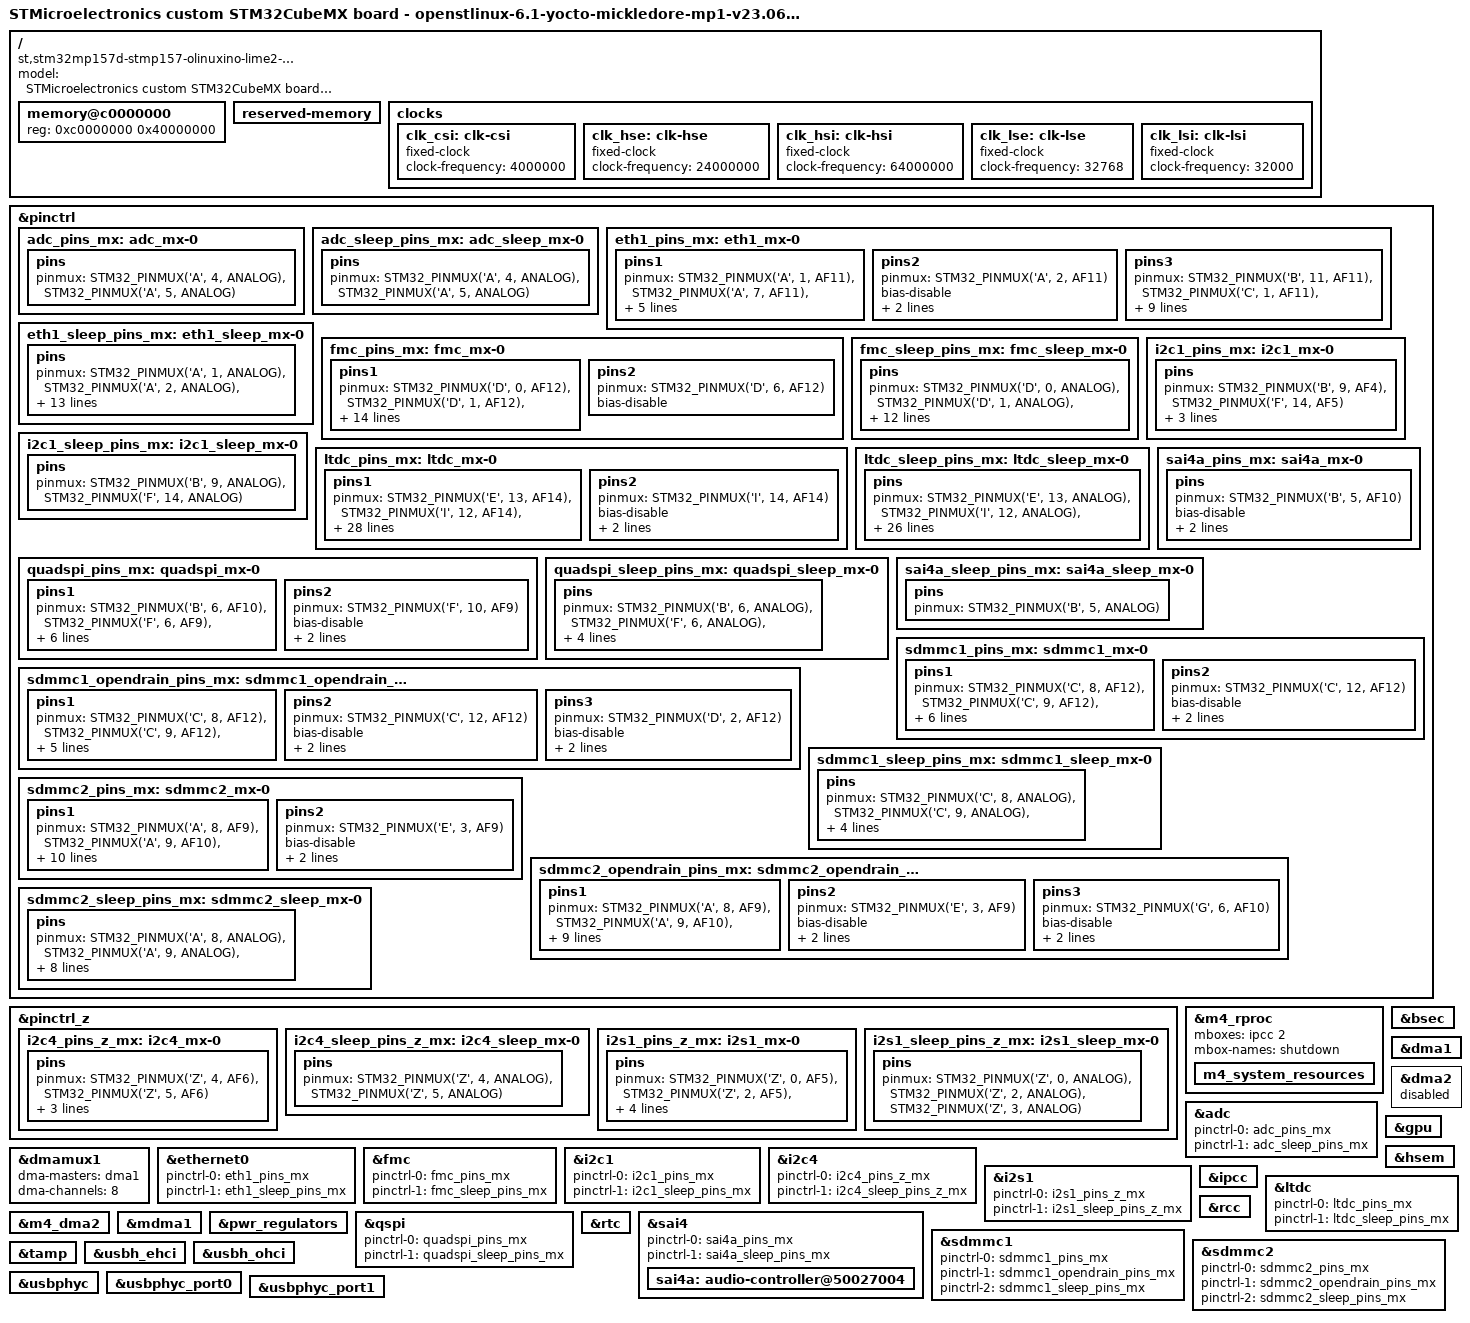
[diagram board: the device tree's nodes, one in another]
// SPDX-License-Identifier: (GPL-2.0-or-later OR BSD-3-Clause)
/*
 * Copyright (C) 2023, STMicroelectronics - All Rights Reserved
 * Author: STM32CubeMX code generation for STMicroelectronics.
 */

/* For more information on Device Tree configuration, please refer to
 * https://wiki.st.com/stm32mpu/wiki/Category:Device_tree_configuration
 */

/dts-v1/;
#include <dt-bindings/pinctrl/stm32-pinfunc.h>

#include "stm32mp157.dtsi"
#include "stm32mp15xd.dtsi"
#include "stm32mp15xxaa-pinctrl.dtsi"
#include "stm32mp15-m4-srm.dtsi"

/* USER CODE BEGIN includes */
#include "stm32mp15-scmi.dtsi"
/* USER CODE END includes */

/ {
	model = "STMicroelectronics custom STM32CubeMX board - openstlinux-6.1-yocto-mickledore-mp1-v23.06.21";
	compatible = "st,stm32mp157d-stmp157-olinuxino-lime2-mx", "st,stm32mp157";

	memory@c0000000 {
		device_type = "memory";
		reg = <0xc0000000 0x40000000>;

		/* USER CODE BEGIN memory */
		/* USER CODE END memory */
	};

	reserved-memory {
		#address-cells = <1>;
		#size-cells = <1>;
		ranges;

		/* USER CODE BEGIN reserved-memory */
		/* USER CODE END reserved-memory */
	};

	/* USER CODE BEGIN root */
	/* USER CODE END root */

	clocks{

		/* USER CODE BEGIN clocks */
		clk_csi: clk-csi {
		#clock-cells = <0>;
		compatible = "fixed-clock";
		clock-frequency = <4000000>;
		};

		clk_hse: clk-hse {
		#clock-cells = <0>;
		compatible = "fixed-clock";
		clock-frequency = <24000000>;
		};

		clk_hsi: clk-hsi {
		#clock-cells = <0>;
		compatible = "fixed-clock";
		clock-frequency = <64000000>;
		};

		clk_lse: clk-lse {
		#clock-cells = <0>;
		compatible = "fixed-clock";
		clock-frequency = <32768>;
		};

		clk_lsi: clk-lsi {
		#clock-cells = <0>;
		compatible = "fixed-clock";
		clock-frequency = <32000>;
		};				
		/* USER CODE END clocks */
	};

}; /*root*/

&pinctrl {

	adc_pins_mx: adc_mx-0 {
		pins {
			pinmux = <STM32_PINMUX('A', 4, ANALOG)>, /* ADC2_INP18 */
					 <STM32_PINMUX('A', 5, ANALOG)>; /* ADC2_INN18 */
		};
	};

	adc_sleep_pins_mx: adc_sleep_mx-0 {
		pins {
			pinmux = <STM32_PINMUX('A', 4, ANALOG)>, /* ADC2_INP18 */
					 <STM32_PINMUX('A', 5, ANALOG)>; /* ADC2_INN18 */
		};
	};

	eth1_pins_mx: eth1_mx-0 {
		pins1 {
			pinmux = <STM32_PINMUX('A', 1, AF11)>, /* ETH1_RX_CLK */
					 <STM32_PINMUX('A', 7, AF11)>, /* ETH1_RX_CTL */
					 <STM32_PINMUX('B', 0, AF11)>, /* ETH1_RXD2 */
					 <STM32_PINMUX('B', 1, AF11)>, /* ETH1_RXD3 */
					 <STM32_PINMUX('C', 4, AF11)>, /* ETH1_RXD0 */
					 <STM32_PINMUX('C', 5, AF11)>; /* ETH1_RXD1 */
			bias-disable;
		};
		pins2 {
			pinmux = <STM32_PINMUX('A', 2, AF11)>; /* ETH1_MDIO */
			bias-disable;
			drive-push-pull;
			slew-rate = <0>;
		};
		pins3 {
			pinmux = <STM32_PINMUX('B', 11, AF11)>, /* ETH1_TX_CTL */
					 <STM32_PINMUX('C', 1, AF11)>, /* ETH1_MDC */
					 <STM32_PINMUX('C', 2, AF11)>, /* ETH1_TXD2 */
					 <STM32_PINMUX('E', 2, AF11)>, /* ETH1_TXD3 */
					 <STM32_PINMUX('G', 4, AF11)>, /* ETH1_GTX_CLK */
					 <STM32_PINMUX('G', 5, AF11)>, /* ETH1_CLK125 */
					 <STM32_PINMUX('G', 13, AF11)>, /* ETH1_TXD0 */
					 <STM32_PINMUX('G', 14, AF11)>; /* ETH1_TXD1 */
			bias-disable;
			drive-push-pull;
			slew-rate = <2>;
		};
	};

	eth1_sleep_pins_mx: eth1_sleep_mx-0 {
		pins {
			pinmux = <STM32_PINMUX('A', 1, ANALOG)>, /* ETH1_RX_CLK */
					 <STM32_PINMUX('A', 2, ANALOG)>, /* ETH1_MDIO */
					 <STM32_PINMUX('A', 7, ANALOG)>, /* ETH1_RX_CTL */
					 <STM32_PINMUX('B', 0, ANALOG)>, /* ETH1_RXD2 */
					 <STM32_PINMUX('B', 1, ANALOG)>, /* ETH1_RXD3 */
					 <STM32_PINMUX('B', 11, ANALOG)>, /* ETH1_TX_CTL */
					 <STM32_PINMUX('C', 1, ANALOG)>, /* ETH1_MDC */
					 <STM32_PINMUX('C', 2, ANALOG)>, /* ETH1_TXD2 */
					 <STM32_PINMUX('C', 4, ANALOG)>, /* ETH1_RXD0 */
					 <STM32_PINMUX('C', 5, ANALOG)>, /* ETH1_RXD1 */
					 <STM32_PINMUX('E', 2, ANALOG)>, /* ETH1_TXD3 */
					 <STM32_PINMUX('G', 4, ANALOG)>, /* ETH1_GTX_CLK */
					 <STM32_PINMUX('G', 5, ANALOG)>, /* ETH1_CLK125 */
					 <STM32_PINMUX('G', 13, ANALOG)>, /* ETH1_TXD0 */
					 <STM32_PINMUX('G', 14, ANALOG)>; /* ETH1_TXD1 */
		};
	};

	fmc_pins_mx: fmc_mx-0 {
		pins1 {
			pinmux = <STM32_PINMUX('D', 0, AF12)>, /* FMC_D2 */
					 <STM32_PINMUX('D', 1, AF12)>, /* FMC_D3 */
					 <STM32_PINMUX('D', 4, AF12)>, /* FMC_NOE */
					 <STM32_PINMUX('D', 5, AF12)>, /* FMC_NWE */
					 <STM32_PINMUX('D', 11, AF12)>, /* FMC_CLE */
					 <STM32_PINMUX('D', 12, AF12)>, /* FMC_ALE */
					 <STM32_PINMUX('D', 14, AF12)>, /* FMC_D0 */
					 <STM32_PINMUX('D', 15, AF12)>, /* FMC_D1 */
					 <STM32_PINMUX('E', 7, AF12)>, /* FMC_D4 */
					 <STM32_PINMUX('E', 8, AF12)>, /* FMC_D5 */
					 <STM32_PINMUX('E', 9, AF12)>, /* FMC_D6 */
					 <STM32_PINMUX('E', 10, AF12)>, /* FMC_D7 */
					 <STM32_PINMUX('G', 9, AF12)>; /* FMC_NCE */
			bias-disable;
			drive-push-pull;
			slew-rate = <1>;
		};
		pins2 {
			pinmux = <STM32_PINMUX('D', 6, AF12)>; /* FMC_NWAIT */
			bias-disable;
		};
	};

	fmc_sleep_pins_mx: fmc_sleep_mx-0 {
		pins {
			pinmux = <STM32_PINMUX('D', 0, ANALOG)>, /* FMC_D2 */
					 <STM32_PINMUX('D', 1, ANALOG)>, /* FMC_D3 */
					 <STM32_PINMUX('D', 4, ANALOG)>, /* FMC_NOE */
					 <STM32_PINMUX('D', 5, ANALOG)>, /* FMC_NWE */
					 <STM32_PINMUX('D', 6, ANALOG)>, /* FMC_NWAIT */
					 <STM32_PINMUX('D', 11, ANALOG)>, /* FMC_CLE */
					 <STM32_PINMUX('D', 12, ANALOG)>, /* FMC_ALE */
					 <STM32_PINMUX('D', 14, ANALOG)>, /* FMC_D0 */
					 <STM32_PINMUX('D', 15, ANALOG)>, /* FMC_D1 */
					 <STM32_PINMUX('E', 7, ANALOG)>, /* FMC_D4 */
					 <STM32_PINMUX('E', 8, ANALOG)>, /* FMC_D5 */
					 <STM32_PINMUX('E', 9, ANALOG)>, /* FMC_D6 */
					 <STM32_PINMUX('E', 10, ANALOG)>, /* FMC_D7 */
					 <STM32_PINMUX('G', 9, ANALOG)>; /* FMC_NCE */
		};
	};

	i2c1_pins_mx: i2c1_mx-0 {
		pins {
			pinmux = <STM32_PINMUX('B', 9, AF4)>, /* I2C1_SDA */
					 <STM32_PINMUX('F', 14, AF5)>; /* I2C1_SCL */
			bias-disable;
			drive-open-drain;
			slew-rate = <0>;
		};
	};

	i2c1_sleep_pins_mx: i2c1_sleep_mx-0 {
		pins {
			pinmux = <STM32_PINMUX('B', 9, ANALOG)>, /* I2C1_SDA */
					 <STM32_PINMUX('F', 14, ANALOG)>; /* I2C1_SCL */
		};
	};

	ltdc_pins_mx: ltdc_mx-0 {
		pins1 {
			pinmux = <STM32_PINMUX('E', 13, AF14)>, /* LTDC_DE */
					 <STM32_PINMUX('I', 12, AF14)>, /* LTDC_HSYNC */
					 <STM32_PINMUX('I', 13, AF14)>, /* LTDC_VSYNC */
					 <STM32_PINMUX('I', 15, AF14)>, /* LTDC_R0 */
					 <STM32_PINMUX('J', 0, AF14)>, /* LTDC_R1 */
					 <STM32_PINMUX('J', 1, AF14)>, /* LTDC_R2 */
					 <STM32_PINMUX('J', 2, AF14)>, /* LTDC_R3 */
					 <STM32_PINMUX('J', 3, AF14)>, /* LTDC_R4 */
					 <STM32_PINMUX('J', 4, AF14)>, /* LTDC_R5 */
					 <STM32_PINMUX('J', 5, AF14)>, /* LTDC_R6 */
					 <STM32_PINMUX('J', 6, AF14)>, /* LTDC_R7 */
					 <STM32_PINMUX('J', 7, AF14)>, /* LTDC_G0 */
					 <STM32_PINMUX('J', 8, AF14)>, /* LTDC_G1 */
					 <STM32_PINMUX('J', 9, AF14)>, /* LTDC_G2 */
					 <STM32_PINMUX('J', 10, AF14)>, /* LTDC_G3 */
					 <STM32_PINMUX('J', 11, AF14)>, /* LTDC_G4 */
					 <STM32_PINMUX('J', 12, AF14)>, /* LTDC_B0 */
					 <STM32_PINMUX('J', 13, AF14)>, /* LTDC_B1 */
					 <STM32_PINMUX('J', 14, AF14)>, /* LTDC_B2 */
					 <STM32_PINMUX('J', 15, AF14)>, /* LTDC_B3 */
					 <STM32_PINMUX('K', 0, AF14)>, /* LTDC_G5 */
					 <STM32_PINMUX('K', 1, AF14)>, /* LTDC_G6 */
					 <STM32_PINMUX('K', 2, AF14)>, /* LTDC_G7 */
					 <STM32_PINMUX('K', 3, AF14)>, /* LTDC_B4 */
					 <STM32_PINMUX('K', 4, AF14)>, /* LTDC_B5 */
					 <STM32_PINMUX('K', 5, AF14)>, /* LTDC_B6 */
					 <STM32_PINMUX('K', 6, AF14)>; /* LTDC_B7 */
			bias-disable;
			drive-push-pull;
			slew-rate = <0>;
		};
		pins2 {
			pinmux = <STM32_PINMUX('I', 14, AF14)>; /* LTDC_CLK */
			bias-disable;
			drive-push-pull;
			slew-rate = <1>;
		};
	};

	ltdc_sleep_pins_mx: ltdc_sleep_mx-0 {
		pins {
			pinmux = <STM32_PINMUX('E', 13, ANALOG)>, /* LTDC_DE */
					 <STM32_PINMUX('I', 12, ANALOG)>, /* LTDC_HSYNC */
					 <STM32_PINMUX('I', 13, ANALOG)>, /* LTDC_VSYNC */
					 <STM32_PINMUX('I', 14, ANALOG)>, /* LTDC_CLK */
					 <STM32_PINMUX('I', 15, ANALOG)>, /* LTDC_R0 */
					 <STM32_PINMUX('J', 0, ANALOG)>, /* LTDC_R1 */
					 <STM32_PINMUX('J', 1, ANALOG)>, /* LTDC_R2 */
					 <STM32_PINMUX('J', 2, ANALOG)>, /* LTDC_R3 */
					 <STM32_PINMUX('J', 3, ANALOG)>, /* LTDC_R4 */
					 <STM32_PINMUX('J', 4, ANALOG)>, /* LTDC_R5 */
					 <STM32_PINMUX('J', 5, ANALOG)>, /* LTDC_R6 */
					 <STM32_PINMUX('J', 6, ANALOG)>, /* LTDC_R7 */
					 <STM32_PINMUX('J', 7, ANALOG)>, /* LTDC_G0 */
					 <STM32_PINMUX('J', 8, ANALOG)>, /* LTDC_G1 */
					 <STM32_PINMUX('J', 9, ANALOG)>, /* LTDC_G2 */
					 <STM32_PINMUX('J', 10, ANALOG)>, /* LTDC_G3 */
					 <STM32_PINMUX('J', 11, ANALOG)>, /* LTDC_G4 */
					 <STM32_PINMUX('J', 12, ANALOG)>, /* LTDC_B0 */
					 <STM32_PINMUX('J', 13, ANALOG)>, /* LTDC_B1 */
					 <STM32_PINMUX('J', 14, ANALOG)>, /* LTDC_B2 */
					 <STM32_PINMUX('J', 15, ANALOG)>, /* LTDC_B3 */
					 <STM32_PINMUX('K', 0, ANALOG)>, /* LTDC_G5 */
					 <STM32_PINMUX('K', 1, ANALOG)>, /* LTDC_G6 */
					 <STM32_PINMUX('K', 2, ANALOG)>, /* LTDC_G7 */
					 <STM32_PINMUX('K', 3, ANALOG)>, /* LTDC_B4 */
					 <STM32_PINMUX('K', 4, ANALOG)>, /* LTDC_B5 */
					 <STM32_PINMUX('K', 5, ANALOG)>, /* LTDC_B6 */
					 <STM32_PINMUX('K', 6, ANALOG)>; /* LTDC_B7 */
		};
	};

	quadspi_pins_mx: quadspi_mx-0 {
		pins1 {
			pinmux = <STM32_PINMUX('B', 6, AF10)>, /* QUADSPI_BK1_NCS */
					 <STM32_PINMUX('F', 6, AF9)>, /* QUADSPI_BK1_IO3 */
					 <STM32_PINMUX('F', 7, AF9)>, /* QUADSPI_BK1_IO2 */
					 <STM32_PINMUX('F', 8, AF10)>, /* QUADSPI_BK1_IO0 */
					 <STM32_PINMUX('F', 9, AF10)>; /* QUADSPI_BK1_IO1 */
			bias-disable;
			drive-push-pull;
			slew-rate = <1>;
		};
		pins2 {
			pinmux = <STM32_PINMUX('F', 10, AF9)>; /* QUADSPI_CLK */
			bias-disable;
			drive-push-pull;
			slew-rate = <2>;
		};
	};

	quadspi_sleep_pins_mx: quadspi_sleep_mx-0 {
		pins {
			pinmux = <STM32_PINMUX('B', 6, ANALOG)>, /* QUADSPI_BK1_NCS */
					 <STM32_PINMUX('F', 6, ANALOG)>, /* QUADSPI_BK1_IO3 */
					 <STM32_PINMUX('F', 7, ANALOG)>, /* QUADSPI_BK1_IO2 */
					 <STM32_PINMUX('F', 8, ANALOG)>, /* QUADSPI_BK1_IO0 */
					 <STM32_PINMUX('F', 9, ANALOG)>, /* QUADSPI_BK1_IO1 */
					 <STM32_PINMUX('F', 10, ANALOG)>; /* QUADSPI_CLK */
		};
	};

	sai4a_pins_mx: sai4a_mx-0 {
		pins {
			pinmux = <STM32_PINMUX('B', 5, AF10)>; /* SAI4_SD_A */
			bias-disable;
			drive-push-pull;
			slew-rate = <0>;
		};
	};

	sai4a_sleep_pins_mx: sai4a_sleep_mx-0 {
		pins {
			pinmux = <STM32_PINMUX('B', 5, ANALOG)>; /* SAI4_SD_A */
		};
	};

	sdmmc1_pins_mx: sdmmc1_mx-0 {
		pins1 {
			pinmux = <STM32_PINMUX('C', 8, AF12)>, /* SDMMC1_D0 */
					 <STM32_PINMUX('C', 9, AF12)>, /* SDMMC1_D1 */
					 <STM32_PINMUX('C', 10, AF12)>, /* SDMMC1_D2 */
					 <STM32_PINMUX('C', 11, AF12)>, /* SDMMC1_D3 */
					 <STM32_PINMUX('D', 2, AF12)>; /* SDMMC1_CMD */
			bias-disable;
			drive-push-pull;
			slew-rate = <1>;
		};
		pins2 {
			pinmux = <STM32_PINMUX('C', 12, AF12)>; /* SDMMC1_CK */
			bias-disable;
			drive-push-pull;
			slew-rate = <3>;
		};
	};

	sdmmc1_opendrain_pins_mx: sdmmc1_opendrain_mx-0 {
		pins1 {
			pinmux = <STM32_PINMUX('C', 8, AF12)>, /* SDMMC1_D0 */
					 <STM32_PINMUX('C', 9, AF12)>, /* SDMMC1_D1 */
					 <STM32_PINMUX('C', 10, AF12)>, /* SDMMC1_D2 */
					 <STM32_PINMUX('C', 11, AF12)>; /* SDMMC1_D3 */
			bias-disable;
			drive-push-pull;
			slew-rate = <1>;
		};
		pins2 {
			pinmux = <STM32_PINMUX('C', 12, AF12)>; /* SDMMC1_CK */
			bias-disable;
			drive-push-pull;
			slew-rate = <3>;
		};
		pins3 {
			pinmux = <STM32_PINMUX('D', 2, AF12)>; /* SDMMC1_CMD */
			bias-disable;
			drive-open-drain;
			slew-rate = <1>;
		};
	};

	sdmmc1_sleep_pins_mx: sdmmc1_sleep_mx-0 {
		pins {
			pinmux = <STM32_PINMUX('C', 8, ANALOG)>, /* SDMMC1_D0 */
					 <STM32_PINMUX('C', 9, ANALOG)>, /* SDMMC1_D1 */
					 <STM32_PINMUX('C', 10, ANALOG)>, /* SDMMC1_D2 */
					 <STM32_PINMUX('C', 11, ANALOG)>, /* SDMMC1_D3 */
					 <STM32_PINMUX('C', 12, ANALOG)>, /* SDMMC1_CK */
					 <STM32_PINMUX('D', 2, ANALOG)>; /* SDMMC1_CMD */
		};
	};

	sdmmc2_pins_mx: sdmmc2_mx-0 {
		pins1 {
			pinmux = <STM32_PINMUX('A', 8, AF9)>, /* SDMMC2_D4 */
					 <STM32_PINMUX('A', 9, AF10)>, /* SDMMC2_D5 */
					 <STM32_PINMUX('B', 3, AF9)>, /* SDMMC2_D2 */
					 <STM32_PINMUX('B', 4, AF9)>, /* SDMMC2_D3 */
					 <STM32_PINMUX('B', 14, AF9)>, /* SDMMC2_D0 */
					 <STM32_PINMUX('B', 15, AF9)>, /* SDMMC2_D1 */
					 <STM32_PINMUX('D', 3, AF9)>, /* SDMMC2_D7 */
					 <STM32_PINMUX('E', 5, AF9)>, /* SDMMC2_D6 */
					 <STM32_PINMUX('G', 6, AF10)>; /* SDMMC2_CMD */
			bias-disable;
			drive-push-pull;
			slew-rate = <1>;
		};
		pins2 {
			pinmux = <STM32_PINMUX('E', 3, AF9)>; /* SDMMC2_CK */
			bias-disable;
			drive-push-pull;
			slew-rate = <3>;
		};
	};

	sdmmc2_opendrain_pins_mx: sdmmc2_opendrain_mx-0 {
		pins1 {
			pinmux = <STM32_PINMUX('A', 8, AF9)>, /* SDMMC2_D4 */
					 <STM32_PINMUX('A', 9, AF10)>, /* SDMMC2_D5 */
					 <STM32_PINMUX('B', 3, AF9)>, /* SDMMC2_D2 */
					 <STM32_PINMUX('B', 4, AF9)>, /* SDMMC2_D3 */
					 <STM32_PINMUX('B', 14, AF9)>, /* SDMMC2_D0 */
					 <STM32_PINMUX('B', 15, AF9)>, /* SDMMC2_D1 */
					 <STM32_PINMUX('D', 3, AF9)>, /* SDMMC2_D7 */
					 <STM32_PINMUX('E', 5, AF9)>; /* SDMMC2_D6 */
			bias-disable;
			drive-push-pull;
			slew-rate = <1>;
		};
		pins2 {
			pinmux = <STM32_PINMUX('E', 3, AF9)>; /* SDMMC2_CK */
			bias-disable;
			drive-push-pull;
			slew-rate = <3>;
		};
		pins3 {
			pinmux = <STM32_PINMUX('G', 6, AF10)>; /* SDMMC2_CMD */
			bias-disable;
			drive-open-drain;
			slew-rate = <1>;
		};
	};

	sdmmc2_sleep_pins_mx: sdmmc2_sleep_mx-0 {
		pins {
			pinmux = <STM32_PINMUX('A', 8, ANALOG)>, /* SDMMC2_D4 */
					 <STM32_PINMUX('A', 9, ANALOG)>, /* SDMMC2_D5 */
					 <STM32_PINMUX('B', 3, ANALOG)>, /* SDMMC2_D2 */
					 <STM32_PINMUX('B', 4, ANALOG)>, /* SDMMC2_D3 */
					 <STM32_PINMUX('B', 14, ANALOG)>, /* SDMMC2_D0 */
					 <STM32_PINMUX('B', 15, ANALOG)>, /* SDMMC2_D1 */
					 <STM32_PINMUX('D', 3, ANALOG)>, /* SDMMC2_D7 */
					 <STM32_PINMUX('E', 3, ANALOG)>, /* SDMMC2_CK */
					 <STM32_PINMUX('E', 5, ANALOG)>, /* SDMMC2_D6 */
					 <STM32_PINMUX('G', 6, ANALOG)>; /* SDMMC2_CMD */
		};
	};

	/* USER CODE BEGIN pinctrl */
	/* USER CODE END pinctrl */
};

&pinctrl_z {

	i2c4_pins_z_mx: i2c4_mx-0 {
		pins {
			pinmux = <STM32_PINMUX('Z', 4, AF6)>, /* I2C4_SCL */
					 <STM32_PINMUX('Z', 5, AF6)>; /* I2C4_SDA */
			bias-disable;
			drive-open-drain;
			slew-rate = <0>;
		};
	};

	i2c4_sleep_pins_z_mx: i2c4_sleep_mx-0 {
		pins {
			pinmux = <STM32_PINMUX('Z', 4, ANALOG)>, /* I2C4_SCL */
					 <STM32_PINMUX('Z', 5, ANALOG)>; /* I2C4_SDA */
		};
	};

	i2s1_pins_z_mx: i2s1_mx-0 {
		pins {
			pinmux = <STM32_PINMUX('Z', 0, AF5)>, /* I2S1_CK */
					 <STM32_PINMUX('Z', 2, AF5)>, /* I2S1_SDO */
					 <STM32_PINMUX('Z', 3, AF5)>; /* I2S1_WS */
			bias-disable;
			drive-push-pull;
			slew-rate = <1>;
		};
	};

	i2s1_sleep_pins_z_mx: i2s1_sleep_mx-0 {
		pins {
			pinmux = <STM32_PINMUX('Z', 0, ANALOG)>, /* I2S1_CK */
					 <STM32_PINMUX('Z', 2, ANALOG)>, /* I2S1_SDO */
					 <STM32_PINMUX('Z', 3, ANALOG)>; /* I2S1_WS */
		};
	};

	/* USER CODE BEGIN pinctrl_z */
	/* USER CODE END pinctrl_z */
};

&m4_rproc{
	/*Restriction: "memory-region" property is not managed - please to use User-Section if needed*/
	mboxes = <&ipcc 2>;
	mbox-names = "shutdown";
	status = "okay";

	/* USER CODE BEGIN m4_rproc */
	/* USER CODE END m4_rproc */

	m4_system_resources{
		status = "okay";

		/* USER CODE BEGIN m4_system_resources */
		/* USER CODE END m4_system_resources */
	};
};

&adc{
	pinctrl-names = "default", "sleep";
	pinctrl-0 = <&adc_pins_mx>;
	pinctrl-1 = <&adc_sleep_pins_mx>;
	status = "okay";

	/* USER CODE BEGIN adc */
	/* USER CODE END adc */
};

&bsec{
	status = "okay";

	/* USER CODE BEGIN bsec */
	/* USER CODE END bsec */
};

&dma1{
	status = "okay";

	/* USER CODE BEGIN dma1 */
	/* USER CODE END dma1 */
};

&dma2{
	status = "disabled";

	/* USER CODE BEGIN dma2 */
	/* USER CODE END dma2 */
};

&dmamux1{
	status = "okay";

	dma-masters = <&dma1>;
	dma-channels = <8>;

	/* USER CODE BEGIN dmamux1 */
	/* USER CODE END dmamux1 */
};

&ethernet0{
	pinctrl-names = "default", "sleep";
	pinctrl-0 = <&eth1_pins_mx>;
	pinctrl-1 = <&eth1_sleep_pins_mx>;
	status = "okay";

	/* USER CODE BEGIN ethernet0 */
	/* USER CODE END ethernet0 */
};

&fmc{
	pinctrl-names = "default", "sleep";
	pinctrl-0 = <&fmc_pins_mx>;
	pinctrl-1 = <&fmc_sleep_pins_mx>;
	status = "okay";

	/* USER CODE BEGIN fmc */
	/* USER CODE END fmc */
};

&gpu{
	status = "okay";

	/* USER CODE BEGIN gpu */
	/* USER CODE END gpu */
};

&hsem{
	status = "okay";

	/* USER CODE BEGIN hsem */
	/* USER CODE END hsem */
};

&i2c1{
	pinctrl-names = "default", "sleep";
	pinctrl-0 = <&i2c1_pins_mx>;
	pinctrl-1 = <&i2c1_sleep_pins_mx>;
	status = "okay";

	/* USER CODE BEGIN i2c1 */
	/* USER CODE END i2c1 */
};

&i2c4{
	pinctrl-names = "default", "sleep";
	pinctrl-0 = <&i2c4_pins_z_mx>;
	pinctrl-1 = <&i2c4_sleep_pins_z_mx>;
	status = "okay";

	/* USER CODE BEGIN i2c4 */
	/* USER CODE END i2c4 */
};

&i2s1{
	pinctrl-names = "default", "sleep";
	pinctrl-0 = <&i2s1_pins_z_mx>;
	pinctrl-1 = <&i2s1_sleep_pins_z_mx>;
	status = "okay";

	/* USER CODE BEGIN i2s1 */
	/* USER CODE END i2s1 */
};

&ipcc{
	status = "okay";

	/* USER CODE BEGIN ipcc */
	/* USER CODE END ipcc */
};

&ltdc{
	pinctrl-names = "default", "sleep";
	pinctrl-0 = <&ltdc_pins_mx>;
	pinctrl-1 = <&ltdc_sleep_pins_mx>;
	status = "okay";

	/* USER CODE BEGIN ltdc */
	/* USER CODE END ltdc */
};

&m4_dma2{
	status = "okay";

	/* USER CODE BEGIN m4_dma2 */
	/* USER CODE END m4_dma2 */
};

&mdma1{
	status = "okay";

	/* USER CODE BEGIN mdma1 */
	/* USER CODE END mdma1 */
};

&pwr_regulators{
	status = "okay";

	/* USER CODE BEGIN pwr_regulators */
	/* USER CODE END pwr_regulators */
};

&qspi{
	pinctrl-names = "default", "sleep";
	pinctrl-0 = <&quadspi_pins_mx>;
	pinctrl-1 = <&quadspi_sleep_pins_mx>;
	status = "okay";

	/* USER CODE BEGIN qspi */
	/* USER CODE END qspi */
};

&rcc{
	status = "okay";

	/* USER CODE BEGIN rcc */
	/* USER CODE END rcc */
};

&rtc{
	status = "okay";

	/* USER CODE BEGIN rtc */
	/* USER CODE END rtc */
};

&sai4{
	pinctrl-names = "default", "sleep";
	pinctrl-0 = <&sai4a_pins_mx>;
	pinctrl-1 = <&sai4a_sleep_pins_mx>;
	status = "okay";

	/* USER CODE BEGIN sai4 */
	/* USER CODE END sai4 */

	sai4a:audio-controller@50027004{
		status = "okay";

		/* USER CODE BEGIN sai4a */
		/* USER CODE END sai4a */
	};
};

&sdmmc1{
	pinctrl-names = "default", "opendrain", "sleep";
	pinctrl-0 = <&sdmmc1_pins_mx>;
	pinctrl-1 = <&sdmmc1_opendrain_pins_mx>;
	pinctrl-2 = <&sdmmc1_sleep_pins_mx>;
	status = "okay";

	/* USER CODE BEGIN sdmmc1 */
	/* USER CODE END sdmmc1 */
};

&sdmmc2{
	pinctrl-names = "default", "opendrain", "sleep";
	pinctrl-0 = <&sdmmc2_pins_mx>;
	pinctrl-1 = <&sdmmc2_opendrain_pins_mx>;
	pinctrl-2 = <&sdmmc2_sleep_pins_mx>;
	status = "okay";

	/* USER CODE BEGIN sdmmc2 */
	/* USER CODE END sdmmc2 */
};

&tamp{
	status = "okay";

	/* USER CODE BEGIN tamp */
	/* USER CODE END tamp */
};

&usbh_ehci{
	status = "okay";

	/* USER CODE BEGIN usbh_ehci */
	/* USER CODE END usbh_ehci */
};

&usbh_ohci{
	status = "okay";

	/* USER CODE BEGIN usbh_ohci */
	/* USER CODE END usbh_ohci */
};

&usbphyc{
	status = "okay";

	/* USER CODE BEGIN usbphyc */
	/* USER CODE END usbphyc */
};

&usbphyc_port0{
	status = "okay";

	/* USER CODE BEGIN usbphyc_port0 */
	/* USER CODE END usbphyc_port0 */
};

&usbphyc_port1{
	status = "okay";

	/* USER CODE BEGIN usbphyc_port1 */
	/* USER CODE END usbphyc_port1 */
};

/* USER CODE BEGIN addons */
/* USER CODE END addons */

